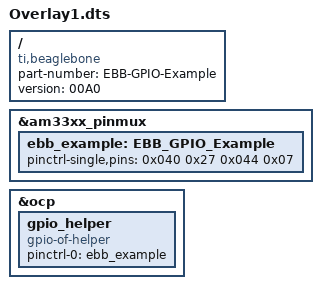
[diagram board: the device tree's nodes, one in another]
/* OUTPUT  GPIO(mode7) 0x07 pulldown, 0x17 pullup, 0x?f no pullup/down */
/* INPUT   GPIO(mode7) 0x27 pulldown, 0x37 pullup, 0x?f no pullup/down */

/* 0x27 (0100111) Fast, Input,  Pull-Down, 	Enabled, Mux Mode 7 	*/
/* 0x37 (0110111) Fast, Input,  Pull-Up, 	Enabled, Mux Mode 7		*/
/* 0x07 (0000111) Fast, Output, Pull-down, 	Enabled, Mux Mode 7		*/
/* 0x17 (0010111) Fast, Output, Pull-up, 	Enabled, Mux Mode 7		*/

/dts-v1/;
/plugin/;

/{
   compatible = "ti,beaglebone", "ti,beaglebone-black";
   part-number = "EBB-GPIO-Example";
   version = "00A0";
   fragment@0 {
      target = <&am33xx_pinmux>;

      __overlay__ {
         ebb_example: EBB_GPIO_Example {
            pinctrl-single,pins = <
               0x040 0x27  // P9_15 $16 GPIO1_16=48 Fast, Input,  Pull-Down, Enabled, Mux Mode 7
               0x044 0x07  // P9_23 $17 GPIO1_17=49 Fast, Output, Pull-down, Enabled, Mux Mode 7
			   
            >;
         };
      };
   };
   fragment@1 {
      target = <&ocp>;
      __overlay__ {
         gpio_helper {
            compatible = "gpio-of-helper";
            status = "okay";
            pinctrl-names = "default";
            pinctrl-0 = <&ebb_example>;
         };
      };
   };
};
